# EZR32LG230F128R67 register map
File version: 5.8.2
CPU: CM3 r2p1, little endian, MPU, no FPU, 3 interrupt priority bits
Registers are 32-bit, read-write, reset 0x0 unless marked. A register's access mark holds for its fields unless they carry their own. Offsets are from the block's base; [hi:lo] are bit positions; {n}, {i} and the like mark numbered series; 'fields as' and 'values as' point back to an identical list.

## DAC0
Base 0x40004000
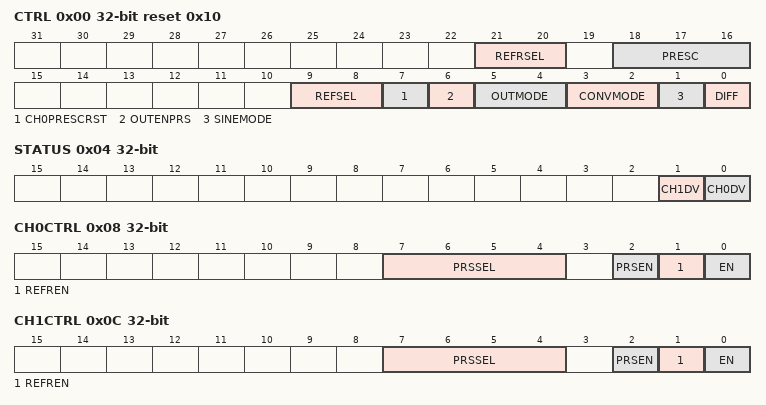
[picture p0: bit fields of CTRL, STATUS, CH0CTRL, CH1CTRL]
0x00 CTRL reset 0x10 — Control Register
  [21:20] REFRSEL — Refresh Interval Select
    0=8CYCLES (All channels with enabled refresh are refreshed every 8 prescaled cycles); 1=16CYCLES (All channels with enabled refresh are refreshed every 16 prescaled cycles); 2=32CYCLES (All channels with enabled refresh are refreshed every 32 prescaled cycles); 3=64CYCLES (All channels with enabled refresh are refreshed every 64 prescaled cycles)
  [18:16] PRESC — Prescaler Setting
    0=NODIVISION
  [9:8] REFSEL — Reference Selection
    0=1V25 (Internal 1.25 V bandgap reference); 1=2V5 (Internal 2.5 V bandgap reference); 2=VDD (VDD reference)
  [7] CH0PRESCRST — Channel 0 Start Reset Prescaler
  [6] OUTENPRS — PRS Controlled Output Enable
  [5:4] OUTMODE — Output Mode
    0=DISABLE (DAC output to pin and ADC disabled); 1=PIN (DAC output to pin enabled. DAC output to ADC and ACMP disabled); 2=ADC (DAC output to pin disabled. DAC output to ADC and ACMP enabled); 3=PINADC (DAC output to pin, ADC, and ACMP enabled)
  [3:2] CONVMODE — Conversion Mode
    0=CONTINUOUS (DAC is set in continuous mode); 1=SAMPLEHOLD (DAC is set in sample/hold mode); 2=SAMPLEOFF (DAC is set in sample/shut off mode)
  [1] SINEMODE
  [0] DIFF — Differential Mode
0x04 STATUS ro
  [1] CH1DV — Channel 1 Data Valid
  [0] CH0DV — Channel 0 Data Valid
0x08 CH0CTRL — Channel 0 Control Register
  [7:4] PRSSEL — Channel 0 PRS Trigger Select
    {v}=PRSCH{v} (PRS ch {v} triggers channel 0 conversion.) (v=0..11)
  [2] PRSEN — Channel 0 PRS Trigger Enable
  [1] REFREN — Channel 0 Automatic Refresh Enable
  [0] EN — Channel 0 Enable
0x0C CH1CTRL — Channel 1 Control Register
  [7:4] PRSSEL — Channel 1 PRS Trigger Select
    {v}=PRSCH{v} (PRS ch {v} triggers channel 1 conversion.) (v=0..11)
  [2] PRSEN — Channel 1 PRS Trigger Enable
  [1] REFREN — Channel 1 Automatic Refresh Enable
  [0] EN — Channel 1 Enable
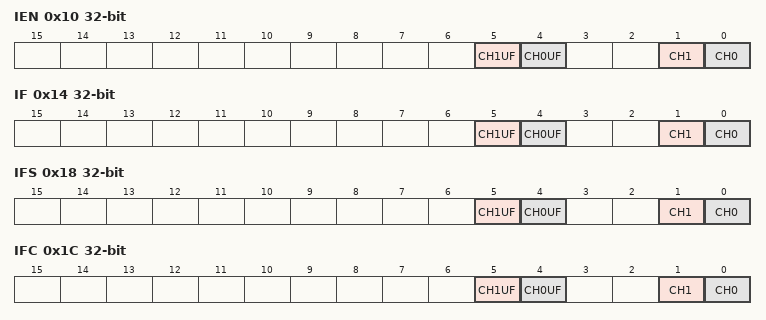
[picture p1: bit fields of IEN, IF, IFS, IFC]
0x10 IEN — Interrupt Enable Register
  [5] CH1UF — Channel 1 Conversion Data Underflow Interrupt Enable
  [4] CH0UF — Channel 0 Conversion Data Underflow Interrupt Enable
  [1] CH1 — Channel 1 Conversion Complete Interrupt Enable
  [0] CH0 — Channel 0 Conversion Complete Interrupt Enable
0x14 IF ro — Interrupt Flag Register
  [5] CH1UF — Channel 1 Data Underflow Interrupt Flag
  [4] CH0UF — Channel 0 Data Underflow Interrupt Flag
  [1] CH1 — Channel 1 Conversion Complete Interrupt Flag
  [0] CH0 — Channel 0 Conversion Complete Interrupt Flag
0x18 IFS wo — Interrupt Flag Set Register
  [5] CH1UF — Channel 1 Data Underflow Interrupt Flag Set
  [4] CH0UF — Channel 0 Data Underflow Interrupt Flag Set
  [1] CH1 — Channel 1 Conversion Complete Interrupt Flag Set
  [0] CH0 — Channel 0 Conversion Complete Interrupt Flag Set
0x1C IFC wo — Interrupt Flag Clear Register
  [5] CH1UF — Channel 1 Data Underflow Interrupt Flag Clear
  [4] CH0UF — Channel 0 Data Underflow Interrupt Flag Clear
  [1] CH1 — Channel 1 Conversion Complete Interrupt Flag Clear
  [0] CH0 — Channel 0 Conversion Complete Interrupt Flag Clear
0x20 CH0DATA — Channel 0 Data Register
  [11:0] DATA — Channel 0 Data
0x24 CH1DATA — Channel 1 Data Register
  [11:0] DATA — Channel 1 Data
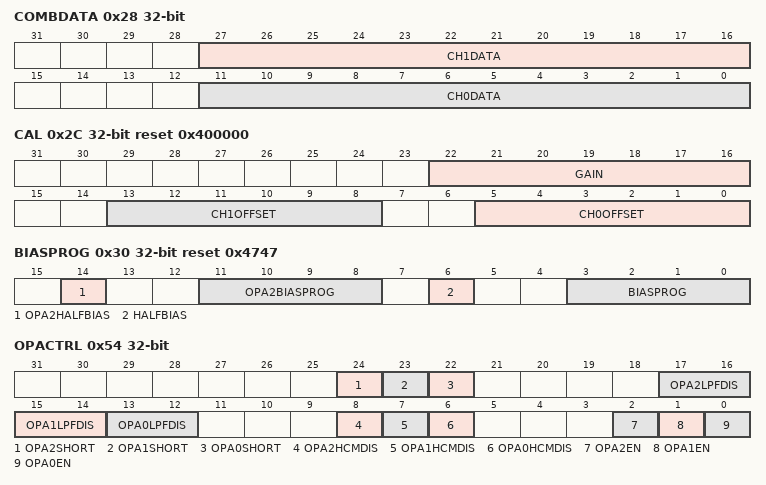
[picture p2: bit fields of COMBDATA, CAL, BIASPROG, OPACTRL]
0x28 COMBDATA wo — Combined Data Register
  [27:16] CH1DATA — Channel 1 Data
  [11:0] CH0DATA — Channel 0 Data
0x2C CAL reset 0x400000 — Calibration Register
  [22:16] GAIN — Gain Calibration Value
  [13:8] CH1OFFSET — Channel 1 Offset Calibration Value
  [5:0] CH0OFFSET — Channel 0 Offset Calibration Value
0x30 BIASPROG reset 0x4747 — Bias Programming Register
  [14] OPA2HALFBIAS — Half Bias Current
  [11:8] OPA2BIASPROG — Bias Programming Value for OPA2
  [6] HALFBIAS — Half Bias Current
  [3:0] BIASPROG — Bias Programming Value
0x54 OPACTRL — Operational Amplifier Control Register
  [24] OPA2SHORT — Short the non-inverting and inverting input.
  [23] OPA1SHORT — Short the non-inverting and inverting input.
  [22] OPA0SHORT — Short the non-inverting and inverting input.
  [17:16] OPA2LPFDIS — Disables Low Pass Filter.
    1=PLPFDIS (Disables the LPF between positive pad and positive input.); 2=NLPFDIS (Disables the LPF between negative pad and negative input.)
  [15:14] OPA1LPFDIS — Disables Low Pass Filter.
    values as OPA2LPFDIS
  [13:12] OPA0LPFDIS — Disables Low Pass Filter.
    values as OPA2LPFDIS
  [8] OPA2HCMDIS — High Common Mode Disable.
  [7] OPA1HCMDIS — High Common Mode Disable.
  [6] OPA0HCMDIS — High Common Mode Disable.
  [2] OPA2EN — OPA2 Enable
  [1] OPA1EN — OPA1 Enable
  [0] OPA0EN — OPA0 Enable
0x58 OPAOFFSET reset 0x20 — Operational Amplifier Offset Register
  [5:0] OPA2OFFSET — OPA2 Offset Configuration Value
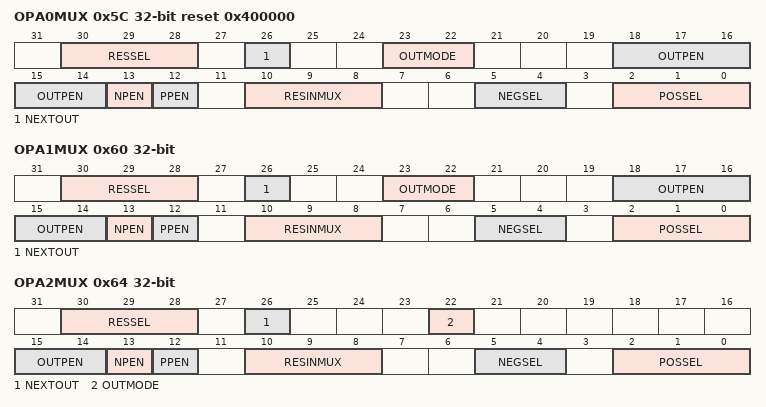
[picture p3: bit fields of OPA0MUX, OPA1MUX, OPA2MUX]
0x5C OPA0MUX reset 0x400000 — Operational Amplifier Mux Configuration Register
  [30:28] RESSEL — OPA0 Resistor Ladder Select
    0=RES0 (Gain of 1/3); 1=RES1 (Gain of 1); 2=RES2 (Gain of 1 2/3); 3=RES3 (Gain of 2); 4=RES4 (Gain of 3); 5=RES5 (Gain of 4 1/3); 6=RES6 (Gain of 7); 7=RES7 (Gain of 15)
  [26] NEXTOUT — OPA0 Next Enable
  [23:22] OUTMODE — Output Select
    0=DISABLE (OPA0 output is disabled); 1=MAIN (Main OPA0 output to pin enabled); 2=ALT (OPA0 alternative output enabled.); 3=ALL (Main OPA0 output drives both main and alternative outputs.)
  [18:14] OUTPEN — OPA0 Output Enable Value
    1=OUT0 (Alternate Output 0); 2=OUT1 (Alternate Output 1); 4=OUT2 (Alternate Output 2); 8=OUT3 (Alternate Output 3); 16=OUT4 (Alternate Output 4)
  [13] NPEN — OPA0 Negative Pad Input Enable
  [12] PPEN — OPA0 Positive Pad Input Enable
  [10:8] RESINMUX — OPA0 Resistor Ladder Input Mux
    0=DISABLE (Set for Unity Gain); 1=OPA0INP (Set for OPA0 input); 2=NEGPAD (NEG pad connected); 3=POSPAD (POS pad connected); 4=VSS (VSS connected)
  [5:4] NEGSEL — OPA0 inverting Input Mux
    0=DISABLE (Input disabled); 1=UG (Unity Gain feedback path); 2=OPATAP (OPA0 Resistor ladder as input); 3=NEGPAD (Input from NEG PAD)
  [2:0] POSSEL — OPA0 non-inverting Input Mux
    0=DISABLE (Input disabled); 1=DAC (DAC as input); 2=POSPAD (POS PAD as input); 3=OPA0INP (OPA0 as input); 4=OPATAP (OPA0 Resistor ladder as input)
0x60 OPA1MUX — Operational Amplifier Mux Configuration Register
  [30:28] RESSEL — OPA1 Resistor Ladder Select
    values as OPA0MUX.RESSEL
  [26] NEXTOUT — OPA1 Next Enable
  [23:22] OUTMODE — Output Select
    0=DISABLE (OPA0 output is disabled); 1=MAIN (Main OPA1 output to pin enabled); 2=ALT (OPA1 alternative output enabled.); 3=ALL (Main OPA1 output drives both main and alternative outputs.)
  [18:14] OUTPEN — OPA1 Output Enable Value
    values as OPA0MUX.OUTPEN
  [13] NPEN — OPA1 Negative Pad Input Enable
  [12] PPEN — OPA1 Positive Pad Input Enable
  [10:8] RESINMUX — OPA1 Resistor Ladder Input Mux
    0=DISABLE (Set for Unity Gain); 1=OPA0INP (Set for OPA0 input); 2=NEGPAD (NEG PAD connected); 3=POSPAD (POS PAD connected); 4=VSS (VSS connected)
  [5:4] NEGSEL — OPA1 inverting Input Mux
    0=DISABLE (Input disabled); 1=UG (Unity Gain feedback path); 2=OPATAP (OPA1 Resistor ladder as input); 3=NEGPAD (Input from NEG PAD)
  [2:0] POSSEL — OPA1 non-inverting Input Mux
    0=DISABLE (Input disabled); 1=DAC (DAC as input); 2=POSPAD (POS PAD as input); 3=OPA0INP (OPA0 as input); 4=OPATAP (OPA 1 Resistor ladder as input)
0x64 OPA2MUX — Operational Amplifier Mux Configuration Register
  [30:28] RESSEL — OPA2 Resistor Ladder Select
    values as OPA0MUX.RESSEL
  [26] NEXTOUT — OPA2 Next Enable
  [22] OUTMODE — Output Select
  [15:14] OUTPEN — OPA2 Output Location
    1=OUT0 (Main Output 0); 2=OUT1 (Main Output 1)
  [13] NPEN — OPA2 Negative Pad Input Enable
  [12] PPEN — OPA2 Positive Pad Input Enable
  [10:8] RESINMUX — OPA2 Resistor Ladder Input Mux
    0=DISABLE (Set for Unity Gain); 1=OPA1INP (Set for OPA1 input); 2=NEGPAD (NEG PAD connected); 3=POSPAD (POS PAD connected); 4=VSS (VSS connected)
  [5:4] NEGSEL — OPA2 inverting Input Mux
    0=DISABLE (Input disabled); 1=UG (Unity Gain feedback path); 2=OPATAP (OPA2 Resistor ladder as input); 3=NEGPAD (Input from NEG PAD)
  [2:0] POSSEL — OPA2 non-inverting Input Mux
    0=DISABLE (Input disabled); 2=POSPAD (POS PAD as input); 3=OPA1INP (OPA1 as input); 4=OPATAP (OPA0 Resistor ladder as input)

## Notices in the file
# License
Copyright 2019 Silicon Laboratories Inc. www.silabs.com
SPDX-License-Identifier: Zlib
The licensor of this software is Silicon Laboratories Inc.
This software is provided 'as-is', without any express or implied
warranty. In no event will the authors be held liable for any damages
arising from the use of this software.
Permission is granted to anyone to use this software for any purpose,
including commercial applications, and to alter it and redistribute it
freely, subject to the following restrictions:
1. The origin of this software must not be misrepresented; you must not
claim that you wrote the original software. If you use this software
in a product, an acknowledgment in the product documentation would be
appreciated but is not required.
2. Altered source versions must be plainly marked as such, and must not be
misrepresented as being the original software.
3. This notice may not be removed or altered from any source distribution.
